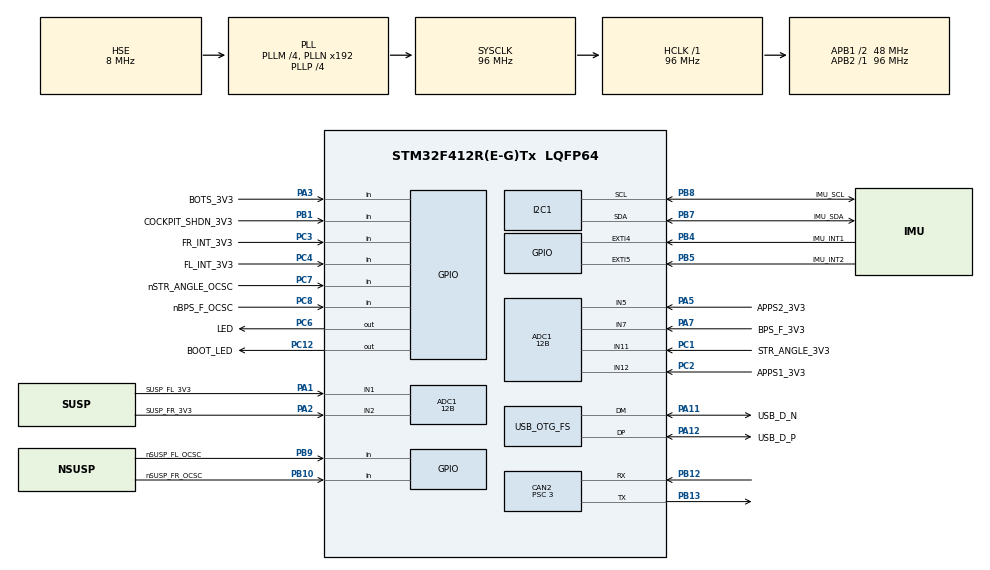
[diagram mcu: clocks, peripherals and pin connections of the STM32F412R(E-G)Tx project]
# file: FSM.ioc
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ADC1.Channel-0\#ChannelRegularConversion=ADC_CHANNEL_1
ADC1.Channel-1\#ChannelRegularConversion=ADC_CHANNEL_2
ADC1.Channel-2\#ChannelRegularConversion=ADC_CHANNEL_5
ADC1.Channel-3\#ChannelRegularConversion=ADC_CHANNEL_7
ADC1.Channel-4\#ChannelRegularConversion=ADC_CHANNEL_11
ADC1.Channel-5\#ChannelRegularConversion=ADC_CHANNEL_12
ADC1.DMAContinuousRequests=ENABLE
ADC1.DataAlign=ADC_DATAALIGN_RIGHT
ADC1.EOCSelection=ADC_EOC_SEQ_CONV
ADC1.EnableAnalogWatchDog=false
ADC1.ExternalTrigConv=ADC_EXTERNALTRIGCONV_T2_TRGO
ADC1.InjNumberOfConversion=0
ADC1.NbrOfConversion=6
ADC1.NbrOfConversionFlag=1
ADC1.Rank-0\#ChannelRegularConversion=1
ADC1.Rank-1\#ChannelRegularConversion=2
ADC1.Rank-2\#ChannelRegularConversion=3
ADC1.Rank-3\#ChannelRegularConversion=4
ADC1.Rank-4\#ChannelRegularConversion=5
ADC1.Rank-5\#ChannelRegularConversion=6
ADC1.Resolution=ADC_RESOLUTION_12B
ADC1.SamplingTime-0\#ChannelRegularConversion=ADC_SAMPLETIME_3CYCLES
ADC1.SamplingTime-1\#ChannelRegularConversion=ADC_SAMPLETIME_3CYCLES
ADC1.SamplingTime-2\#ChannelRegularConversion=ADC_SAMPLETIME_3CYCLES
ADC1.SamplingTime-3\#ChannelRegularConversion=ADC_SAMPLETIME_3CYCLES
ADC1.SamplingTime-4\#ChannelRegularConversion=ADC_SAMPLETIME_3CYCLES
ADC1.SamplingTime-5\#ChannelRegularConversion=ADC_SAMPLETIME_3CYCLES
ADC1.ScanConvMode=ENABLE
ADC1.master=1
CAN2.ABOM=ENABLE
CAN2.BS1=CAN_BS1_12TQ
CAN2.BS2=CAN_BS2_3TQ
CAN2.CalculateBaudRate=1000000
CAN2.CalculateTimeBit=1000
CAN2.CalculateTimeQuantum=62.5
CAN2.NART=ENABLE
CAN2.Prescaler=3
CAN2.RFLM=ENABLE
CAN2.SJW=CAN_SJW_3TQ
CAN2.TXFP=ENABLE
Dma.ADC1.0.Direction=DMA_PERIPH_TO_MEMORY
Dma.ADC1.0.FIFOMode=DMA_FIFOMODE_DISABLE
Dma.ADC1.0.Instance=DMA2_Stream0
Dma.ADC1.0.MemDataAlignment=DMA_MDATAALIGN_HALFWORD
Dma.ADC1.0.MemInc=DMA_MINC_ENABLE
Dma.ADC1.0.Mode=DMA_CIRCULAR
Dma.ADC1.0.PeriphDataAlignment=DMA_PDATAALIGN_HALFWORD
Dma.ADC1.0.PeriphInc=DMA_PINC_DISABLE
Dma.ADC1.0.Priority=DMA_PRIORITY_LOW
Dma.Request0=ADC1
FREERTOS.Tasks01=Task1kHz,48,512,RunTask1kHz,Default,NULL,Static,Task1kHzBuffer,Task1kHzControlBlock;Task100Hz,40,512,RunTask100Hz,Default,NULL,Static,Task100HzBuffer,Task100HzControlBlock;Task1Hz,32,512,RunTask1Hz,Default,NULL,Static,Task1HzBuffer,Task1HzControlBlock;TaskCanTx,24,512,RunTaskCanTx,Default,NULL,Static,TaskCanTxBuffer,TaskCanTxControlBlock;TaskCanRx,24,512,RunTaskCanRx,Default,NULL,Static,TaskCanRxBuffer,TaskCanRxControlBlock;TaskChimera,40,512,RunTaskChimera,Default,NULL,Static,TaskChimeraBuffer,TaskChimeraControlBlock
FREERTOS.configGENERATE_RUN_TIME_STATS=1
FREERTOS.configUSE_STATS_FORMATTING_FUNCTIONS=1
I2C1.DutyCycle=I2C_DUTYCYCLE_2
I2C1.I2C_Mode=I2C_Fast
IWDG.Reload=LSI_FREQUENCY / IWDG_PRESCALER / IWDG_RESET_FREQUENCY
Mcu.Family=STM32F4
Mcu.Name=STM32F412R(E-G)Tx
Mcu.Package=LQFP64
Mcu.UserConstants=IWDG_RESET_FREQUENCY,5;TIM2_ARR,TIMx_FREQUENCY / (TIM2_PRESCALER * TIM2_FREQUENCY);TIM2_PRESCALER,4;IWDG_PRESCALER,4;LSI_FREQUENCY,32000;TIM2_FREQUENCY,1000;TIMx_FREQUENCY,96000000
NVIC.ADC_IRQn=true\:5\:0\:false\:false\:true\:true\:true\:true\:true
NVIC.CAN2_RX0_IRQn=true\:5\:0\:false\:false\:true\:true\:true\:true\:true
NVIC.CAN2_RX1_IRQn=true\:5\:0\:false\:false\:true\:true\:true\:true\:true
NVIC.CAN2_SCE_IRQn=true\:5\:0\:false\:false\:true\:true\:true\:true\:true
NVIC.CAN2_TX_IRQn=true\:5\:0\:false\:false\:true\:true\:true\:true\:true
NVIC.DMA2_Stream0_IRQn=true\:5\:0\:false\:false\:true\:true\:false\:true\:true
NVIC.EXTI9_5_IRQn=true\:5\:0\:false\:false\:true\:true\:true\:true\:true
NVIC.I2C1_ER_IRQn=true\:5\:0\:false\:false\:true\:true\:true\:true\:true
NVIC.I2C1_EV_IRQn=true\:5\:0\:false\:false\:true\:true\:true\:true\:true
NVIC.OTG_FS_IRQn=true\:5\:0\:false\:false\:true\:true\:true\:true\:true
NVIC.PriorityGroup=NVIC_PRIORITYGROUP_4
NVIC.TIM6_IRQn=true\:15\:0\:false\:false\:true\:false\:false\:true\:true
NVIC.TIM7_IRQn=true\:5\:0\:false\:false\:true\:true\:true\:true\:true
NVIC.TimeBase=TIM6_IRQn
NVIC.TimeBaseIP=TIM6
PA1.GPIO_Label=SUSP_FL_3V3
PA1.Signal=ADCx_IN1
PA11.GPIO_Label=USB_D_N
PA11.Mode=Device_Only
PA11.Signal=USB_OTG_FS_DM
PA12.GPIO_Label=USB_D_P
PA12.Mode=Device_Only
PA12.Signal=USB_OTG_FS_DP
PA13.GPIO_Label=SWDIO
PA13.Mode=Trace_Asynchronous_SW
PA13.Signal=SYS_JTMS-SWDIO
PA14.GPIO_Label=SWCLK
PA14.Mode=Trace_Asynchronous_SW
PA14.Signal=SYS_JTCK-SWCLK
PA2.GPIO_Label=SUSP_FR_3V3
PA2.Signal=ADCx_IN2
PA3.GPIO_Label=BOTS_3V3
PA3.Signal=GPIO_Input
PA5.GPIO_Label=APPS2_3V3
PA5.Signal=ADCx_IN5
PA7.GPIO_Label=BPS_F_3V3
PA7.Signal=ADCx_IN7
PB1.GPIO_Label=COCKPIT_SHDN_3V3
PB1.Signal=GPIO_Input
PB10.GPIO_Label=nSUSP_FR_OCSC
PB10.Signal=GPIO_Input
PB12.Mode=CAN_Activate
PB12.Signal=CAN2_RX
PB13.Mode=CAN_Activate
PB13.Signal=CAN2_TX
PB3.GPIO_Label=SWO
PB3.Mode=Trace_Asynchronous_SW
PB3.Signal=SYS_JTDO-SWO
PB4.GPIO_Label=IMU_INT1
PB4.Signal=GPXTI4
PB5.GPIO_Label=IMU_INT2
PB5.Signal=GPXTI5
PB7.GPIO_Label=IMU_SDA
PB7.Mode=I2C
PB7.Signal=I2C1_SDA
PB8.GPIO_Label=IMU_SCL
PB8.Mode=I2C
PB8.Signal=I2C1_SCL
PB9.GPIO_Label=nSUSP_FL_OCSC
PB9.Signal=GPIO_Input
PC1.GPIO_Label=STR_ANGLE_3V3
PC1.Signal=ADCx_IN11
PC12.GPIO_Label=BOOT_LED
PC12.Signal=GPIO_Output
PC2.GPIO_Label=APPS1_3V3
PC2.Signal=ADCx_IN12
PC3.GPIO_Label=FR_INT_3V3
PC3.Signal=GPIO_Input
PC4.GPIO_Label=FL_INT_3V3
PC4.Signal=GPIO_Input
PC6.GPIO_Label=LED
PC6.Signal=GPIO_Output
PC7.GPIO_Label=nSTR_ANGLE_OCSC
PC7.Signal=GPIO_Input
PC8.GPIO_Label=nBPS_F_OCSC
PC8.Signal=GPIO_Input
PH0\ -\ OSC_IN.Mode=HSE-External-Oscillator
PH0\ -\ OSC_IN.Signal=RCC_OSC_IN
PH1\ -\ OSC_OUT.Mode=HSE-External-Oscillator
PH1\ -\ OSC_OUT.Signal=RCC_OSC_OUT
ProjectManager.HeapSize=0x200
ProjectManager.StackSize=0x400
ProjectManager.TargetToolchain=EWARM V8.50
RCC.AHBFreq_Value=96000000
RCC.APB1CLKDivider=RCC_HCLK_DIV2
RCC.APB1Freq_Value=48000000
RCC.APB1TimFreq_Value=96000000
RCC.APB2Freq_Value=96000000
RCC.APB2TimFreq_Value=96000000
RCC.CortexFreq_Value=96000000
RCC.HCLKFreq_Value=96000000
RCC.HSE_VALUE=8000000
RCC.PLLM=4
RCC.PLLP=RCC_PLLP_DIV4
RCC.PLLQ=8
RCC.SYSCLKFreq_VALUE=96000000
RCC.SYSCLKSource=RCC_SYSCLKSOURCE_PLLCLK
RCC.USBFreq_Value=48000000
RCC.VCOOutputFreq_Value=384000000
SH.ADCx_IN1.0=ADC1_IN1,IN1
SH.ADCx_IN11.0=ADC1_IN11,IN11
SH.ADCx_IN12.0=ADC1_IN12,IN12
SH.ADCx_IN2.0=ADC1_IN2,IN2
SH.ADCx_IN5.0=ADC1_IN5,IN5
SH.ADCx_IN7.0=ADC1_IN7,IN7
TIM2.Period=TIM2_ARR - 1
TIM2.Prescaler=TIM2_PRESCALER - 1
TIM2.TIM_MasterOutputTrigger=TIM_TRGO_UPDATE
TIM7.Period=960-1
TIM7.Prescaler=10-1
USB_DEVICE.CLASS_NAME_FS=CDC
USB_DEVICE.MANUFACTURER_STRING=ubc_formula_electric
USB_DEVICE.PRODUCT_STRING_CDC_FS=fsm
USB_DEVICE.VirtualMode=Cdc
USB_DEVICE.VirtualModeFS=Cdc_FS
USB_OTG_FS.VirtualMode=Device_Only
VP_FREERTOS_VS_CMSIS_V2.Mode=CMSIS_V2
VP_IWDG_VS_IWDG.Mode=IWDG_Activate
VP_SYS_VS_tim6.Mode=TIM6
VP_TIM2_VS_ClockSourceINT.Mode=Internal
VP_TIM7_VS_ClockSourceINT.Mode=Enable_Timer
VP_USB_DEVICE_VS_USB_DEVICE_CDC_FS.Mode=CDC_FS
board=custom

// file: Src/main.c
/* USER CODE BEGIN Header */
/**
 ******************************************************************************
 * @file           : main.c
 * @brief          : Main program body
 ******************************************************************************
 * @attention
 *
 * Copyright (c) 2024 STMicroelectronics.
 * All rights reserved.
 *
 * This software is licensed under terms that can be found in the LICENSE file
 * in the root directory of this software component.
 * If no LICENSE file comes with this software, it is provided AS-IS.
 *
 ******************************************************************************
 */
/* USER CODE END Header */
#include "main.h"
#include "cmsis_os.h"
#include "usb_device.h"

/* USER CODE BEGIN Includes */
#include "tasks.h"
#include "hw_runTimeStat.h"
/* USER CODE END Includes */

typedef StaticTask_t osStaticThreadDef_t;

ADC_HandleTypeDef hadc1;
DMA_HandleTypeDef hdma_adc1;

CAN_HandleTypeDef hcan2;

I2C_HandleTypeDef hi2c1;

IWDG_HandleTypeDef hiwdg;

TIM_HandleTypeDef htim2;
TIM_HandleTypeDef htim7;

/* Definitions for Task1kHz */
osThreadId_t         Task1kHzHandle;
uint32_t             Task1kHzBuffer[512];
osStaticThreadDef_t  Task1kHzControlBlock;
const osThreadAttr_t Task1kHz_attributes = {
    .name       = "Task1kHz",
    .cb_mem     = &Task1kHzControlBlock,
    .cb_size    = sizeof(Task1kHzControlBlock),
    .stack_mem  = &Task1kHzBuffer[0],
    .stack_size = sizeof(Task1kHzBuffer),
    .priority   = (osPriority_t)osPriorityRealtime,
};
/* Definitions for Task100Hz */
osThreadId_t         Task100HzHandle;
uint32_t             Task100HzBuffer[512];
osStaticThreadDef_t  Task100HzControlBlock;
const osThreadAttr_t Task100Hz_attributes = {
    .name       = "Task100Hz",
    .cb_mem     = &Task100HzControlBlock,
    .cb_size    = sizeof(Task100HzControlBlock),
    .stack_mem  = &Task100HzBuffer[0],
    .stack_size = sizeof(Task100HzBuffer),
    .priority   = (osPriority_t)osPriorityHigh,
};
/* Definitions for Task1Hz */
osThreadId_t         Task1HzHandle;
uint32_t             Task1HzBuffer[512];
osStaticThreadDef_t  Task1HzControlBlock;
const osThreadAttr_t Task1Hz_attributes = {
    .name       = "Task1Hz",
    .cb_mem     = &Task1HzControlBlock,
    .cb_size    = sizeof(Task1HzControlBlock),
    .stack_mem  = &Task1HzBuffer[0],
    .stack_size = sizeof(Task1HzBuffer),
    .priority   = (osPriority_t)osPriorityAboveNormal,
};
/* Definitions for TaskCanTx */
osThreadId_t         TaskCanTxHandle;
uint32_t             TaskCanTxBuffer[512];
osStaticThreadDef_t  TaskCanTxControlBlock;
const osThreadAttr_t TaskCanTx_attributes = {
    .name       = "TaskCanTx",
    .cb_mem     = &TaskCanTxControlBlock,
    .cb_size    = sizeof(TaskCanTxControlBlock),
    .stack_mem  = &TaskCanTxBuffer[0],
    .stack_size = sizeof(TaskCanTxBuffer),
    .priority   = (osPriority_t)osPriorityNormal,
};
/* Definitions for TaskCanRx */
osThreadId_t         TaskCanRxHandle;
uint32_t             TaskCanRxBuffer[512];
osStaticThreadDef_t  TaskCanRxControlBlock;
const osThreadAttr_t TaskCanRx_attributes = {
    .name       = "TaskCanRx",
    .cb_mem     = &TaskCanRxControlBlock,
    .cb_size    = sizeof(TaskCanRxControlBlock),
    .stack_mem  = &TaskCanRxBuffer[0],
    .stack_size = sizeof(TaskCanRxBuffer),
    .priority   = (osPriority_t)osPriorityNormal,
};
/* Definitions for TaskChimera */
osThreadId_t         TaskChimeraHandle;
uint32_t             TaskChimeraBuffer[512];
osStaticThreadDef_t  TaskChimeraControlBlock;
const osThreadAttr_t TaskChimera_attributes = {
    .name       = "TaskChimera",
    .cb_mem     = &TaskChimeraControlBlock,
    .cb_size    = sizeof(TaskChimeraControlBlock),
    .stack_mem  = &TaskChimeraBuffer[0],
    .stack_size = sizeof(TaskChimeraBuffer),
    .priority   = (osPriority_t)osPriorityHigh,
};

void        SystemClock_Config(void);
static void MX_GPIO_Init(void);
static void MX_DMA_Init(void);
static void MX_ADC1_Init(void);
static void MX_CAN2_Init(void);
static void MX_I2C1_Init(void);
static void MX_TIM2_Init(void);
static void MX_IWDG_Init(void);
static void MX_TIM7_Init(void);
void        RunTask1kHz(void *argument);
void        RunTask100Hz(void *argument);
void        RunTask1Hz(void *argument);
void        RunTaskCanTx(void *argument);
void        RunTaskCanRx(void *argument);
void        RunTaskChimera(void *argument);

int main(void)
{
    /* USER CODE BEGIN 1 */
    tasks_preInit();
    /* USER CODE END 1 */

    /* MCU Configuration--------------------------------------------------------*/

    /* Reset of all peripherals, Initializes the Flash interface and the Systick. */
    HAL_Init();

    /* Configure the system clock */
    SystemClock_Config();

    /* Initialize all configured peripherals */
    MX_GPIO_Init();
    MX_DMA_Init();
    MX_ADC1_Init();
    MX_CAN2_Init();
    MX_I2C1_Init();
    MX_TIM2_Init();
    MX_IWDG_Init();
    MX_TIM7_Init();

    tasks_init();
    /* Init scheduler */
    osKernelInitialize();

    /* Create the thread(s) */
    /* creation of Task1kHz */
    Task1kHzHandle = osThreadNew(RunTask1kHz, NULL, &Task1kHz_attributes);

    /* creation of Task100Hz */
    Task100HzHandle = osThreadNew(RunTask100Hz, NULL, &Task100Hz_attributes);

    /* creation of Task1Hz */
    Task1HzHandle = osThreadNew(RunTask1Hz, NULL, &Task1Hz_attributes);

    /* creation of TaskCanTx */
    TaskCanTxHandle = osThreadNew(RunTaskCanTx, NULL, &TaskCanTx_attributes);

    /* creation of TaskCanRx */
    TaskCanRxHandle = osThreadNew(RunTaskCanRx, NULL, &TaskCanRx_attributes);

    /* creation of TaskChimera */
    TaskChimeraHandle = osThreadNew(RunTaskChimera, NULL, &TaskChimera_attributes);

    /* Start scheduler */
    osKernelStart();

    /* We should never get here as control is now taken by the scheduler */

    /* Infinite loop */
    while (1)
    {

    }
}

void SystemClock_Config(void)
{
    RCC_OscInitTypeDef RCC_OscInitStruct = { 0 };
    RCC_ClkInitTypeDef RCC_ClkInitStruct = { 0 };

    /** Configure the main internal regulator output voltage
     */
    __HAL_RCC_PWR_CLK_ENABLE();
    __HAL_PWR_VOLTAGESCALING_CONFIG(PWR_REGULATOR_VOLTAGE_SCALE1);

    /** Initializes the RCC Oscillators according to the specified parameters
     * in the RCC_OscInitTypeDef structure.
     */
    RCC_OscInitStruct.OscillatorType = RCC_OSCILLATORTYPE_LSI | RCC_OSCILLATORTYPE_HSE;
    RCC_OscInitStruct.HSEState       = RCC_HSE_ON;
    RCC_OscInitStruct.LSIState       = RCC_LSI_ON;
    RCC_OscInitStruct.PLL.PLLState   = RCC_PLL_ON;
    RCC_OscInitStruct.PLL.PLLSource  = RCC_PLLSOURCE_HSE;
    RCC_OscInitStruct.PLL.PLLM       = 4;
    RCC_OscInitStruct.PLL.PLLN       = 192;
    RCC_OscInitStruct.PLL.PLLP       = RCC_PLLP_DIV4;
    RCC_OscInitStruct.PLL.PLLQ       = 8;
    RCC_OscInitStruct.PLL.PLLR       = 2;
    if (HAL_RCC_OscConfig(&RCC_OscInitStruct) != HAL_OK)
    {
        Error_Handler();
    }

    /** Initializes the CPU, AHB and APB buses clocks
     */
    RCC_ClkInitStruct.ClockType = RCC_CLOCKTYPE_HCLK | RCC_CLOCKTYPE_SYSCLK | RCC_CLOCKTYPE_PCLK1 | RCC_CLOCKTYPE_PCLK2;
    RCC_ClkInitStruct.SYSCLKSource   = RCC_SYSCLKSOURCE_PLLCLK;
    RCC_ClkInitStruct.AHBCLKDivider  = RCC_SYSCLK_DIV1;
    RCC_ClkInitStruct.APB1CLKDivider = RCC_HCLK_DIV2;
    RCC_ClkInitStruct.APB2CLKDivider = RCC_HCLK_DIV1;

    if (HAL_RCC_ClockConfig(&RCC_ClkInitStruct, FLASH_LATENCY_3) != HAL_OK)
    {
        Error_Handler();
    }
}

static void MX_ADC1_Init(void)
{

    ADC_ChannelConfTypeDef sConfig = { 0 };

    /** Configure the global features of the ADC (Clock, Resolution, Data Alignment and number of conversion)
     */
    hadc1.Instance                   = ADC1;
    hadc1.Init.ClockPrescaler        = ADC_CLOCK_SYNC_PCLK_DIV4;
    hadc1.Init.Resolution            = ADC_RESOLUTION_12B;
    hadc1.Init.ScanConvMode          = ENABLE;
    hadc1.Init.ContinuousConvMode    = DISABLE;
    hadc1.Init.DiscontinuousConvMode = DISABLE;
    hadc1.Init.ExternalTrigConvEdge  = ADC_EXTERNALTRIGCONVEDGE_RISING;
    hadc1.Init.ExternalTrigConv      = ADC_EXTERNALTRIGCONV_T2_TRGO;
    hadc1.Init.DataAlign             = ADC_DATAALIGN_RIGHT;
    hadc1.Init.NbrOfConversion       = 6;
    hadc1.Init.DMAContinuousRequests = ENABLE;
    hadc1.Init.EOCSelection          = ADC_EOC_SEQ_CONV;
    if (HAL_ADC_Init(&hadc1) != HAL_OK)
    {
        Error_Handler();
    }

    /** Configure for the selected ADC regular channel its corresponding rank in the sequencer and its sample time.
     */
    sConfig.Channel      = ADC_CHANNEL_1;
    sConfig.Rank         = 1;
    sConfig.SamplingTime = ADC_SAMPLETIME_3CYCLES;
    if (HAL_ADC_ConfigChannel(&hadc1, &sConfig) != HAL_OK)
    {
        Error_Handler();
    }

    /** Configure for the selected ADC regular channel its corresponding rank in the sequencer and its sample time.
     */
    sConfig.Channel = ADC_CHANNEL_2;
    sConfig.Rank    = 2;
    if (HAL_ADC_ConfigChannel(&hadc1, &sConfig) != HAL_OK)
    {
        Error_Handler();
    }

    /** Configure for the selected ADC regular channel its corresponding rank in the sequencer and its sample time.
     */
    sConfig.Channel = ADC_CHANNEL_5;
    sConfig.Rank    = 3;
    if (HAL_ADC_ConfigChannel(&hadc1, &sConfig) != HAL_OK)
    {
        Error_Handler();
    }

    /** Configure for the selected ADC regular channel its corresponding rank in the sequencer and its sample time.
     */
    sConfig.Channel = ADC_CHANNEL_7;
    sConfig.Rank    = 4;
    if (HAL_ADC_ConfigChannel(&hadc1, &sConfig) != HAL_OK)
    {
        Error_Handler();
    }

    /** Configure for the selected ADC regular channel its corresponding rank in the sequencer and its sample time.
     */
    sConfig.Channel = ADC_CHANNEL_11;
    sConfig.Rank    = 5;
    if (HAL_ADC_ConfigChannel(&hadc1, &sConfig) != HAL_OK)
    {
        Error_Handler();
    }

    /** Configure for the selected ADC regular channel its corresponding rank in the sequencer and its sample time.
     */
    sConfig.Channel = ADC_CHANNEL_12;
    sConfig.Rank    = 6;
    if (HAL_ADC_ConfigChannel(&hadc1, &sConfig) != HAL_OK)
    {
        Error_Handler();
    }
}

static void MX_CAN2_Init(void)
{

    hcan2.Instance                  = CAN2;
    hcan2.Init.Prescaler            = 3;
    hcan2.Init.Mode                 = CAN_MODE_NORMAL;
    hcan2.Init.SyncJumpWidth        = CAN_SJW_3TQ;
    hcan2.Init.TimeSeg1             = CAN_BS1_12TQ;
    hcan2.Init.TimeSeg2             = CAN_BS2_3TQ;
    hcan2.Init.TimeTriggeredMode    = DISABLE;
    hcan2.Init.AutoBusOff           = ENABLE;
    hcan2.Init.AutoWakeUp           = DISABLE;
    hcan2.Init.AutoRetransmission   = ENABLE;
    hcan2.Init.ReceiveFifoLocked    = ENABLE;
    hcan2.Init.TransmitFifoPriority = ENABLE;
    if (HAL_CAN_Init(&hcan2) != HAL_OK)
    {
        Error_Handler();
    }
}

static void MX_I2C1_Init(void)
{

    hi2c1.Instance             = I2C1;
    hi2c1.Init.ClockSpeed      = 400000;
    hi2c1.Init.DutyCycle       = I2C_DUTYCYCLE_2;
    hi2c1.Init.OwnAddress1     = 0;
    hi2c1.Init.AddressingMode  = I2C_ADDRESSINGMODE_7BIT;
    hi2c1.Init.DualAddressMode = I2C_DUALADDRESS_DISABLE;
    hi2c1.Init.OwnAddress2     = 0;
    hi2c1.Init.GeneralCallMode = I2C_GENERALCALL_DISABLE;
    hi2c1.Init.NoStretchMode   = I2C_NOSTRETCH_DISABLE;
    if (HAL_I2C_Init(&hi2c1) != HAL_OK)
    {
        Error_Handler();
    }
}

static void MX_IWDG_Init(void)
{
    /* USER CODE BEGIN IWDG_Init 0 */
#ifndef WATCHDOG_DISABLED
    /* USER CODE END IWDG_Init 0 */

    hiwdg.Instance       = IWDG;
    hiwdg.Init.Prescaler = IWDG_PRESCALER_4;
    hiwdg.Init.Reload    = LSI_FREQUENCY / IWDG_PRESCALER / IWDG_RESET_FREQUENCY;
    if (HAL_IWDG_Init(&hiwdg) != HAL_OK)
    {
        Error_Handler();
    }
    /* USER CODE BEGIN IWDG_Init 2 */
#endif
    /* USER CODE END IWDG_Init 2 */
}

static void MX_TIM2_Init(void)
{

    TIM_ClockConfigTypeDef  sClockSourceConfig = { 0 };
    TIM_MasterConfigTypeDef sMasterConfig      = { 0 };

    htim2.Instance               = TIM2;
    htim2.Init.Prescaler         = TIM2_PRESCALER - 1;
    htim2.Init.CounterMode       = TIM_COUNTERMODE_UP;
    htim2.Init.Period            = TIM2_ARR - 1;
    htim2.Init.ClockDivision     = TIM_CLOCKDIVISION_DIV1;
    htim2.Init.AutoReloadPreload = TIM_AUTORELOAD_PRELOAD_DISABLE;
    if (HAL_TIM_Base_Init(&htim2) != HAL_OK)
    {
        Error_Handler();
    }
    sClockSourceConfig.ClockSource = TIM_CLOCKSOURCE_INTERNAL;
    if (HAL_TIM_ConfigClockSource(&htim2, &sClockSourceConfig) != HAL_OK)
    {
        Error_Handler();
    }
    sMasterConfig.MasterOutputTrigger = TIM_TRGO_UPDATE;
    sMasterConfig.MasterSlaveMode     = TIM_MASTERSLAVEMODE_DISABLE;
    if (HAL_TIMEx_MasterConfigSynchronization(&htim2, &sMasterConfig) != HAL_OK)
    {
        Error_Handler();
    }
}

static void MX_TIM7_Init(void)
{

    htim7.Instance               = TIM7;
    htim7.Init.Prescaler         = 10 - 1;
    htim7.Init.CounterMode       = TIM_COUNTERMODE_UP;
    htim7.Init.Period            = 960 - 1;
    htim7.Init.AutoReloadPreload = TIM_AUTORELOAD_PRELOAD_DISABLE;
    if (HAL_TIM_Base_Init(&htim7) != HAL_OK)
    {
        Error_Handler();
    }
}

static void MX_DMA_Init(void)
{
    /* DMA controller clock enable */
    __HAL_RCC_DMA2_CLK_ENABLE();

    /* DMA interrupt init */
    /* DMA2_Stream0_IRQn interrupt configuration */
    HAL_NVIC_SetPriority(DMA2_Stream0_IRQn, 5, 0);
    HAL_NVIC_EnableIRQ(DMA2_Stream0_IRQn);
}

static void MX_GPIO_Init(void)
{
    GPIO_InitTypeDef GPIO_InitStruct = { 0 };

    /* GPIO Ports Clock Enable */
    __HAL_RCC_GPIOH_CLK_ENABLE();
    __HAL_RCC_GPIOC_CLK_ENABLE();
    __HAL_RCC_GPIOA_CLK_ENABLE();
    __HAL_RCC_GPIOB_CLK_ENABLE();

    /*Configure GPIO pin Output Level */
    HAL_GPIO_WritePin(GPIOC, LED_Pin | BOOT_LED_Pin, GPIO_PIN_RESET);

    /*Configure GPIO pins : FR_INT_3V3_Pin FL_INT_3V3_Pin nSTR_ANGLE_OCSC_Pin nBPS_F_OCSC_Pin */
    GPIO_InitStruct.Pin  = FR_INT_3V3_Pin | FL_INT_3V3_Pin | nSTR_ANGLE_OCSC_Pin | nBPS_F_OCSC_Pin;
    GPIO_InitStruct.Mode = GPIO_MODE_INPUT;
    GPIO_InitStruct.Pull = GPIO_NOPULL;
    HAL_GPIO_Init(GPIOC, &GPIO_InitStruct);

    /*Configure GPIO pin : BOTS_3V3_Pin */
    GPIO_InitStruct.Pin  = BOTS_3V3_Pin;
    GPIO_InitStruct.Mode = GPIO_MODE_INPUT;
    GPIO_InitStruct.Pull = GPIO_NOPULL;
    HAL_GPIO_Init(BOTS_3V3_GPIO_Port, &GPIO_InitStruct);

    /*Configure GPIO pins : COCKPIT_SHDN_3V3_Pin nSUSP_FR_OCSC_Pin nSUSP_FL_OCSC_Pin */
    GPIO_InitStruct.Pin  = COCKPIT_SHDN_3V3_Pin | nSUSP_FR_OCSC_Pin | nSUSP_FL_OCSC_Pin;
    GPIO_InitStruct.Mode = GPIO_MODE_INPUT;
    GPIO_InitStruct.Pull = GPIO_NOPULL;
    HAL_GPIO_Init(GPIOB, &GPIO_InitStruct);

    /*Configure GPIO pins : LED_Pin BOOT_LED_Pin */
    GPIO_InitStruct.Pin   = LED_Pin | BOOT_LED_Pin;
    GPIO_InitStruct.Mode  = GPIO_MODE_OUTPUT_PP;
    GPIO_InitStruct.Pull  = GPIO_NOPULL;
    GPIO_InitStruct.Speed = GPIO_SPEED_FREQ_LOW;
    HAL_GPIO_Init(GPIOC, &GPIO_InitStruct);

    /*Configure GPIO pins : IMU_INT1_Pin IMU_INT2_Pin */
    GPIO_InitStruct.Pin  = IMU_INT1_Pin | IMU_INT2_Pin;
    GPIO_InitStruct.Mode = GPIO_MODE_IT_RISING;
    GPIO_InitStruct.Pull = GPIO_NOPULL;
    HAL_GPIO_Init(GPIOB, &GPIO_InitStruct);

    /* EXTI interrupt init*/
    HAL_NVIC_SetPriority(EXTI9_5_IRQn, 5, 0);
    HAL_NVIC_EnableIRQ(EXTI9_5_IRQn);

}

void RunTask1kHz(void *argument)
{
    /* init code for USB_DEVICE */
    MX_USB_DEVICE_Init();
    /* USER CODE BEGIN 5 */
    tasks_run1kHz();
    /* USER CODE END 5 */
}

void RunTask100Hz(void *argument)
{
    /* USER CODE BEGIN RunTask100Hz */
    tasks_run100Hz();
    /* USER CODE END RunTask100Hz */
}

void RunTask1Hz(void *argument)
{
    /* USER CODE BEGIN RunTask1Hz */
    tasks_run1Hz();
    /* USER CODE END RunTask1Hz */
}

void RunTaskCanTx(void *argument)
{
    /* USER CODE BEGIN RunTaskCanTx */
    tasks_runCanTx();
    /* USER CODE END RunTaskCanTx */
}

void RunTaskCanRx(void *argument)
{
    /* USER CODE BEGIN RunTaskCanRx */
    tasks_runCanRx();
    /* USER CODE END RunTaskCanRx */
}

void RunTaskChimera(void *argument)
{
    /* USER CODE BEGIN RunTaskChimera */
    /* Infinite loop */
    tasks_runChimera();
    /* USER CODE END RunTaskChimera */
}

void HAL_TIM_PeriodElapsedCallback(TIM_HandleTypeDef *htim)
{
    if (htim->Instance == TIM6)
    {
        HAL_IncTick();
    }
    /* USER CODE BEGIN Callback 1 */
    else if (htim->Instance == TIM7)
    {
        ulHighFrequencyTimerTick++;
    }
    /* USER CODE END Callback 1 */
}

void Error_Handler(void)
{
    __disable_irq();
    while (1)
    {
    }
}
